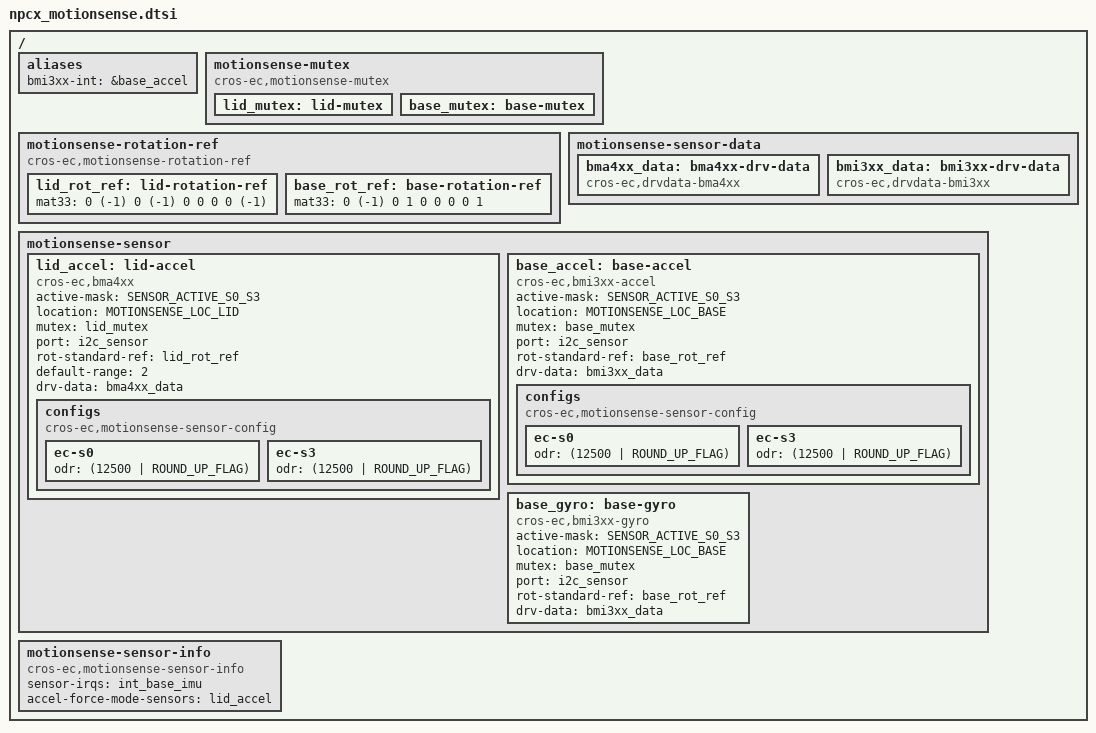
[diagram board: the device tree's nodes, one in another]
/* Copyright 2022 The ChromiumOS Authors
 * Use of this source code is governed by a BSD-style license that can be
 * found in the LICENSE file.
 */

/*
 * Kingler and Steelix use the same dts, take care of this when modify it.
 */

#include <dt-bindings/motionsense/utils.h>

/ {
	aliases {
		/*
		 * motion sense's <>_INT_EVENT is handled
		 * by alias. Using the alias, each driver creates
		 * its own <>_INT_EVENT.
		 */
		bmi3xx-int = &base_accel;
	};

	/*
	 * Declare mutexes used by sensor drivers.
	 * A mutex node is used to create an instance of mutex_t.
	 * A mutex node is referenced by a sensor node if the
	 * corresponding sensor driver needs to use the
	 * instance of the mutex.
	 */
	motionsense-mutex {
		compatible = "cros-ec,motionsense-mutex";
		lid_mutex: lid-mutex {
		};
		base_mutex: base-mutex {
		};
	};

	/* Rotation matrix used by drivers. */
	motionsense-rotation-ref {
		compatible = "cros-ec,motionsense-rotation-ref";
		lid_rot_ref: lid-rotation-ref {
			mat33 = <0 (-1) 0
				 (-1) 0 0
				 0 0 (-1)>;
		};
		base_rot_ref: base-rotation-ref {
			mat33 = <0 (-1) 0
				 1 0 0
				 0 0 1>;
		};
	};

	/*
	 * Driver specific data. A driver-specific data can be shared with
	 * different motion sensors while they are using the same driver.
	 *
	 * If a node's compatible starts with "cros-ec,accelgyro-", it is for
	 * a common structure defined in accelgyro.h.
	 * e.g) compatible = "cros-ec,accelgyro-als-drv-data" is for
	 * "struct als_drv_data_t" in accelgyro.h
	 */
	motionsense-sensor-data {
		bma4xx_data: bma4xx-drv-data {
			compatible = "cros-ec,drvdata-bma4xx";
			status = "okay";
		};
		bmi3xx_data: bmi3xx-drv-data {
			compatible = "cros-ec,drvdata-bmi3xx";
			status = "okay";
		};
	};

	/*
	 * List of motion sensors that creates motion_sensors array.
	 * The nodelabel "lid_accel" and "base_accel" are used to indicate
	 * motion sensor IDs for lid angle calculation.
	 */
	motionsense-sensor {
		lid_accel: lid-accel {
			compatible = "cros-ec,bma4xx";
			status = "okay";

			active-mask = "SENSOR_ACTIVE_S0_S3";
			location = "MOTIONSENSE_LOC_LID";
			mutex = <&lid_mutex>;
			port = <&i2c_sensor>;
			rot-standard-ref = <&lid_rot_ref>;
			default-range = <2>;
			drv-data = <&bma4xx_data>;
			configs {
				compatible =
					"cros-ec,motionsense-sensor-config";
				ec-s0 {
					odr = <(12500 | ROUND_UP_FLAG)>;
				};
				ec-s3 {
					odr = <(12500 | ROUND_UP_FLAG)>;
				};
			};
		};

		base_accel: base-accel {
			compatible = "cros-ec,bmi3xx-accel";
			status = "okay";

			active-mask = "SENSOR_ACTIVE_S0_S3";
			location = "MOTIONSENSE_LOC_BASE";
			mutex = <&base_mutex>;
			port = <&i2c_sensor>;
			rot-standard-ref = <&base_rot_ref>;
			drv-data = <&bmi3xx_data>;
			configs {
				compatible =
					"cros-ec,motionsense-sensor-config";
				ec-s0 {
					odr = <(12500 | ROUND_UP_FLAG)>;
				};
				ec-s3 {
					odr = <(12500 | ROUND_UP_FLAG)>;
				};
			};
		};

		base_gyro: base-gyro {
			compatible = "cros-ec,bmi3xx-gyro";
			status = "okay";

			active-mask = "SENSOR_ACTIVE_S0_S3";
			location = "MOTIONSENSE_LOC_BASE";
			mutex = <&base_mutex>;
			port = <&i2c_sensor>;
			rot-standard-ref = <&base_rot_ref>;
			drv-data = <&bmi3xx_data>;
		};

	};

	motionsense-sensor-info {
		compatible = "cros-ec,motionsense-sensor-info";

		/*
		 * list of GPIO interrupts that have to
		 * be enabled at initial stage
		 */
		sensor-irqs = <&int_base_imu>;
		/* list of sensors in force mode */
		accel-force-mode-sensors = <&lid_accel>;
	};
};
